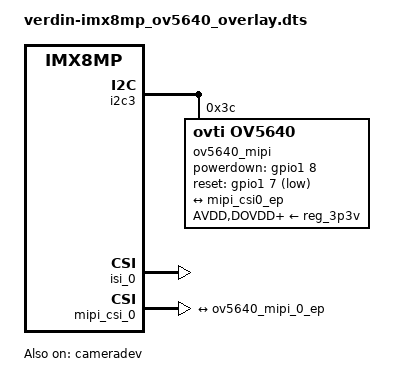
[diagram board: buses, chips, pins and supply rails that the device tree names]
// SPDX-License-Identifier: GPL-2.0-or-later OR MIT
/*
 * Copyright 2020-2021 Toradex
 */

// CSI Camera Module 5MP OV5640 previously orderable at Toradex.

/dts-v1/;
/plugin/;

#include <dt-bindings/clock/imx8mp-clock.h>
#include <dt-bindings/gpio/gpio.h>

/ {
	compatible = "toradex,verdin-imx8mp";
};

&cameradev {
	status = "okay";
};

/* Verdin I2C_4_CSI */
&i2c3 {
	#address-cells = <1>;
	#size-cells = <0>;
	status = "okay";

	ov5640_mipi@3c {
		assigned-clocks = <&clk IMX8MP_CLK_IPP_DO_CLKO2>;
		assigned-clock-parents = <&clk IMX8MP_CLK_24M>;
		assigned-clock-rates = <24000000>;
		AVDD-supply = <&reg_3p3v>;
		compatible = "ovti,ov5640";
		clock-names = "xclk";
		clocks = <&clk IMX8MP_CLK_IPP_DO_CLKO2>;
		csi_id = <0>;
		DOVDD-supply = <&reg_3p3v>;
		DVDD-supply = <&reg_3p3v>;
		mclk = <24000000>;
		mclk_source = <0>;
		mipi_csi;
		pinctrl-names = "default";
		pinctrl-0 = <&pinctrl_gpio5>, <&pinctrl_gpio6>;
		powerdown-gpios = <&gpio1 8 GPIO_ACTIVE_HIGH>;
		PVDD-supply = <&reg_3p3v>;
		reg = <0x3c>;
		reset-gpios = <&gpio1 7 GPIO_ACTIVE_LOW>;
		status = "okay";

		port {
			ov5640_mipi_0_ep: endpoint {
				clock-lanes = <0>;
				data-lanes = <1 2>;
				remote-endpoint = <&mipi_csi0_ep>;
			};
		};
	};
};

&isi_0 {
	status = "okay";

	cap_device {
		status = "okay";
	};

	m2m_device {
		status = "okay";
	};
};

&mipi_csi_0 {
	#address-cells = <1>;
	#size-cells = <0>;
	status = "okay";

	port@0 {
		reg = <0>;

		mipi_csi0_ep: endpoint {
			csis-hs-settle = <13>;
			csis-clk-settle = <2>;
			csis-wclk;
			data-lanes = <2>;
			remote-endpoint = <&ov5640_mipi_0_ep>;
		};
	};
};
